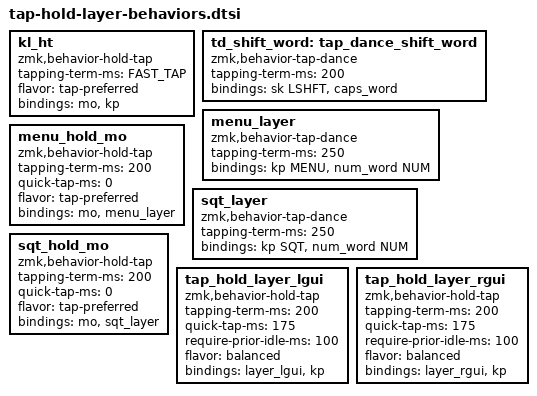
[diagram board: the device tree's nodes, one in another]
// define a behavior key_layer_<layer>_<key> which produces <&kp key>
// on single tap, <&mo layer> on hold, and <&tog layer> on double-tap
    kl_ht: kl_ht {
        compatible = "zmk,behavior-hold-tap";
        #binding-cells = <2>;
        tapping-term-ms = <FAST_TAP>;
        flavor = "tap-preferred";
        bindings = <&mo>, <&kp>;
    };

#define ZMK_KEY_LAYER(key, layer) \
    key_layer_##key##_##layer: key_layer_##key##_##layer { \
        compatible = "zmk,behavior-tap-dance"; \
        #binding-cells = <0>; \
        tapping-term-ms = <FAST_TAP>; \
        bindings = <&kl_ht layer key>, <&tog layer>; \
    };



td_shift_word: tap_dance_shift_word {
        compatible = "zmk,behavior-tap-dance";
        #binding-cells = <0>;
        tapping-term-ms = <200>;
        bindings = <&sk LSHFT>, <&caps_word>;
};



menu_layer: menu_layer {
    compatible = "zmk,behavior-tap-dance";
    #binding-cells = <0>;
    tapping-term-ms = <250>; // 200 is too low
    bindings = <&kp MENU>, <&num_word NUM>;
};
        
menu_hold_mo: menu_hold_mo {
    compatible = "zmk,behavior-hold-tap";
    #binding-cells = <2>;
    tapping-term-ms = <200>;
    quick-tap-ms = <0>;
    flavor = "tap-preferred";
    bindings = <&mo>, <&menu_layer>;
};

sqt_layer: sqt_layer {
    compatible = "zmk,behavior-tap-dance";
    #binding-cells = <0>;
    tapping-term-ms = <250>; // 200 is too low
    bindings = <&kp SQT>, <&num_word NUM>;
};
        
sqt_hold_mo: sqt_hold_mo {
    compatible = "zmk,behavior-hold-tap";
    #binding-cells = <2>;
    tapping-term-ms = <200>;
    quick-tap-ms = <0>;
    flavor = "tap-preferred";
    bindings = <&mo>, <&sqt_layer>;
};


/*
 * tap_hold_layer_lgui: Tap for keypress, hold for layer activation with LGUI modifier
 * 
 * This behavior allows tapping a key for its normal function, while holding it
 * activates both a layer and the LGUI (Left GUI/Windows/Command) modifier simultaneously.
 * 
 * Usage: &tap_hold_layer_lgui <LAYER_TO_ACTIVATE> <KEY_TO_TAP>
 * Example: &tap_hold_layer_lgui NAVIGATION F  // Tap for F, hold for NAVIGATION layer + LGUI
 */

tap_hold_layer_lgui: tap_hold_layer_lgui {
    compatible = "zmk,behavior-hold-tap";
    #binding-cells = <2>;
    tapping-term-ms = <200>;
    quick-tap-ms = <175>;
    require-prior-idle-ms = <100>;
    flavor = "balanced";
    bindings = <&layer_lgui>, <&kp>;
};

tap_hold_layer_rgui: tap_hold_layer_rgui {
    compatible = "zmk,behavior-hold-tap";
    #binding-cells = <2>;
    tapping-term-ms = <200>;
    quick-tap-ms = <175>;
    require-prior-idle-ms = <100>;
    flavor = "balanced";
    bindings = <&layer_rgui>, <&kp>;
};


/*
Usage examples in keymap:

&tap_hold_layer_lgui NUMERIC F      // Tap F, hold for layer NUMERIC + LGUI
&tap_hold_layer_lctrl SYMBOLS J     // Tap J, hold for layer SYMBOLS + LCTRL

Available modifiers:
- tap_hold_layer_lgui
- tap_hold_layer_rgui
*/
